# HR_C7000_DM32 register map
Vendor: Dahua Technology (chip); Baofeng (radio product); Series: HR_C7000; File version: 0.1-dm32re-draft
CPU: other r0p0, little endian, no MPU, no FPU, 0 interrupt priority bits
Registers are 32-bit, read-write, reset 0x0 unless marked. A register's access mark holds for its fields unless they carry their own. Offsets are from the block's base; [hi:lo] are bit positions.

## UART0 — UART0, Synopsys DesignWare APB UART, 16550-compatible (DS §5.4, p.268-285). Offsets 0x00/0x04/0x08 are shared: RBR/THR/DLL, IER/DLH (selected by LCR.DLAB) and IIR/FCR (read/write). FW: 28 access sites.
Base 0x14030000
Same registers: UART1 0x14040000, UART2 0x14050000, UART3 0x14090000
0x00 RBR ro — Receive buffer register. DS §5.4.5.1 p.274. FW: 2 reads, 7 writes. Reset 0x0 (DS).
  [7:0] RBR — Receive buffer: data received on the serial input port [reset 0x0] [access RO]
0x00 THR wo (alternate view of RBR) — Transmit Holding Register. DS §5.4.5.2 p.275. FW: 2 reads, 7 writes. Reset 0x0 (DS).
  [7:0] THR — Transmit holding: data sent to the serial port [reset 0x0] [access WO]
0x00 DLL (alternate view of RBR) — Frequency division latch low. DS §5.4.5.3 p.275. FW: 2 reads, 7 writes. Reset 0x0 (DS).
  [7:0] DLL — Divisor latch low: low 8 bits of the baud-rate divisor (requires LCR.DLAB=1) [reset 0x0] [access RW]
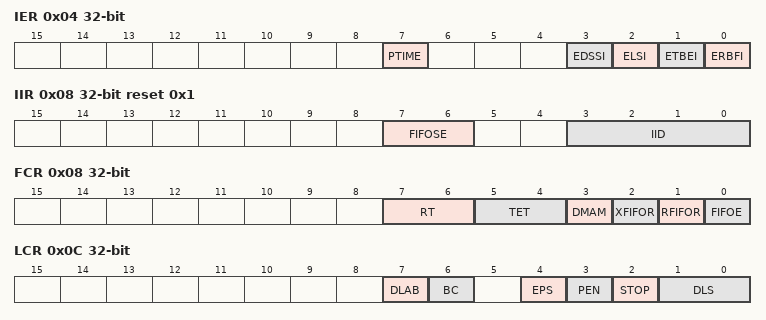
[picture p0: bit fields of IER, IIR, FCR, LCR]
0x04 IER — Interrupt enable register. DS §5.4.5.5 p.275. FW: 0 reads, 2 writes. Reset 0x0 (DS).
  [7] PTIME — Used to enable/disable the generation of THRE interrupt. 0 = disabled 1 = enabled [reset 0x0] [access RW]
  [3] EDSSI — Enable modem status interrupt. 0 = disabled 1 = enabled [reset 0x0] [access RW]
  [2] ELSI — Enable receiver line status interrupt 0 = disabled 1 = enabled [reset 0x0] [access RW]
  [1] ETBEI — Enable transmit holding register empty interrupt 0 = disabled 1 = enabled [reset 0x0] [access RW]
  [0] ERBFI — Enable receive data available interrupt and character timeout interrupt ( FIFO mode ) 0 = disabled 1 = enabled [reset 0x0] [access RW]
0x04 DLH (alternate view of IER) — Frequency division latch high. DS §5.4.5.4 p.275. FW: 0 reads, 2 writes. Reset 0x0 (DS).
  [7:0] DLH — Divisor latch high: high 8 bits of the baud-rate divisor (requires LCR.DLAB=1) [reset 0x0] [access RW]
0x08 IIR ro reset 0x1 — Interrupt Flag Register. DS §5.4.5.6 p.277. FW: 0 reads, 2 writes. Reset 0x1 (DS).
  [7:6] FIFOSE — FIFOs enabled. 00: disabled; 11: enabled [reset 0x0] [access RO]
  [3:0] IID — Interrupt ID, highest-priority pending: 0001 none; 0110 receiver line status (highest; cleared by reading LSR); 0100 received data available (second; cleared when RX FIFO drops below threshold); 1100 character timeout (second; cleared by reading RBR); 0010 THR empty (third; cleared by reading IIR or TX FIFO above threshold); 0111 busy detect (not available in 16550-compatible mode) [reset 0x1] [access RO]
0x08 FCR wo (alternate view of IIR) — FIFO Controller Registers. DS §5.4.5.7 p.279. FW: 0 reads, 2 writes. Reset 0x0 (DS).
  [7:6] RT — RCVR trigger, RX-data-available threshold. 00: 1 char; 01: 1/4 FIFO (4); 10: 1/2 FIFO (8); 11: FIFO depth - 2 (14) [reset 0x0] [access WO]
  [5:4] TET — TX empty trigger. 00: FIFO empty; 01: 2 chars; 10: 1/4 FIFO (4); 11: 1/2 FIFO (8) [reset 0x0] [access WO]
  [3] DMAM — DMA mode. 0: mode 0; 1: mode 1 [reset 0x0] [access WO]
  [2] XFIFOR — XMIT FIFO reset [reset 0x0] [access WO]
  [1] RFIFOR — RCVR FIFO reset [reset 0x0] [access WO]
  [0] FIFOE — FIFO enable (both TX and RX FIFOs) [reset 0x0] [access WO]
0x0C LCR — Line Control Register. DS §5.4.5.8 p.279. FW: 4 reads, 2 writes. Bit 5 (stick parity) is reserved and reads as 0. Reset 0x0 (DS).
  [7] DLAB — Divisor latch access: enables DLL/DLH at offsets 0x00/0x04. Must be cleared after the baud rate is set [reset 0x0] [access RW]
  [6] BC — Break control: 1 forces the serial output to the break state. Printed 'Break' [reset 0x0] [access RW]
  [4] EPS — Even parity select. 1: even; 0: odd [reset 0x0] [access RW]
  [3] PEN — Parity enable. 0: disabled; 1: enabled [reset 0x0] [access RW]
  [2] STOP — Stop bits. 0: 1 stop bit; 1: 1.5 stop bits when DLS=0, else 2. The receiver checks only the first stop bit [reset 0x0] [access RW]
  [1:0] DLS — Data length. 00: 5 bits; 01: 6; 10: 7; 11: 8 [reset 0x0] [access RW]
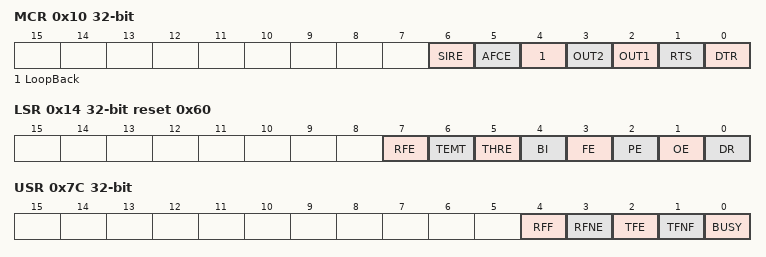
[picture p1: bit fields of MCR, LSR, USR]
0x10 MCR — Modem Control registers. DS §5.4.5.9 p.281. Reset 0x0 (DS).
  [6] SIRE — SIR mode enabled [reset 0x0] [access RW]
  [5] AFCE — Automatic flow control [reset 0x0] [access RW]
  [4] LoopBack — Loop Mode [reset 0x0] [access RW]
  [3] OUT2 — OUT2 [reset 0x0] [access RW]
  [2] OUT1 — OUT1 [reset 0x0] [access RW]
  [1] RTS — RTS [reset 0x0] [access RW]
  [0] DTR — DTR [reset 0x0] [access RW]
0x14 LSR ro reset 0x60 — Line Status Register. DS §5.4.5.10 p.281. FW: 5 reads, 0 writes. Reset 0x60 (DS).
  [7] RFE — Receiver FIFO error: at least one parity, framing or break error in the FIFO [reset 0x0] [access RO]
  [6] TEMT — Transmitter empty: in FIFO mode, set when both the transmit shift register and the FIFO are empty [reset 0x1] [access RO]
  [5] THRE — THR empty. With IER.PTIME=1 it means the TX FIFO is FULL; with IER.PTIME=0 it means the TX FIFO is EMPTY [reset 0x1] [access RO]
  [4] BI — Break interrupt: serial input held at 0 for longer than one character time [reset 0x0] [access RO]
  [3] FE — Framing error: no valid stop bit received [reset 0x0] [access RO]
  [2] PE — Parity error [reset 0x0] [access RO]
  [1] OE — Overrun error: data received while the FIFO was full; the FIFO keeps its data, the shift-register byte is lost [reset 0x0] [access RO]
  [0] DR — Data ready: at least one character in RBR or the RX FIFO [reset 0x0] [access RO]
0x7C USR ro — FIFO Status Flags. DS §5.4.5.11 p.283. FW: 4 reads, 0 writes. Reset 0x0 (DS).
  [4] RFF — Receive FIFO full [reset 0x0] [access RO]
  [3] RFNE — Receive FIFO not empty [reset 0x0] [access RO]
  [2] TFE — Transmit FIFO empty [reset 0x0] [access RO]
  [1] TFNF — Transmit FIFO not full [reset 0x0] [access RO]
  [0] BUSY — UART busy. The datasheet says only 'This bit is invalid' [reset 0x0] [access RO]
0x80 TFL ro — The amount of data in the transmit FIFO. DS §5.4.5.12 p.285. Reset 0x0 (DS).
  [4:0] TFL — Transmit FIFO level (number of entries). Printed width [FIFO_ADDR_WIDTH:0]; [4:0] assumes the 16-deep FIFO implied by FCR's thresholds (INFERRED) [reset 0x0] [access RO]
0x84 RFL ro — DS §5.4.5.13 p.285. Reset 0x0 (DS).
  [4:0] RFL — Receive FIFO level (number of entries). Width INFERRED as for TFL [reset 0x0] [access RO]
